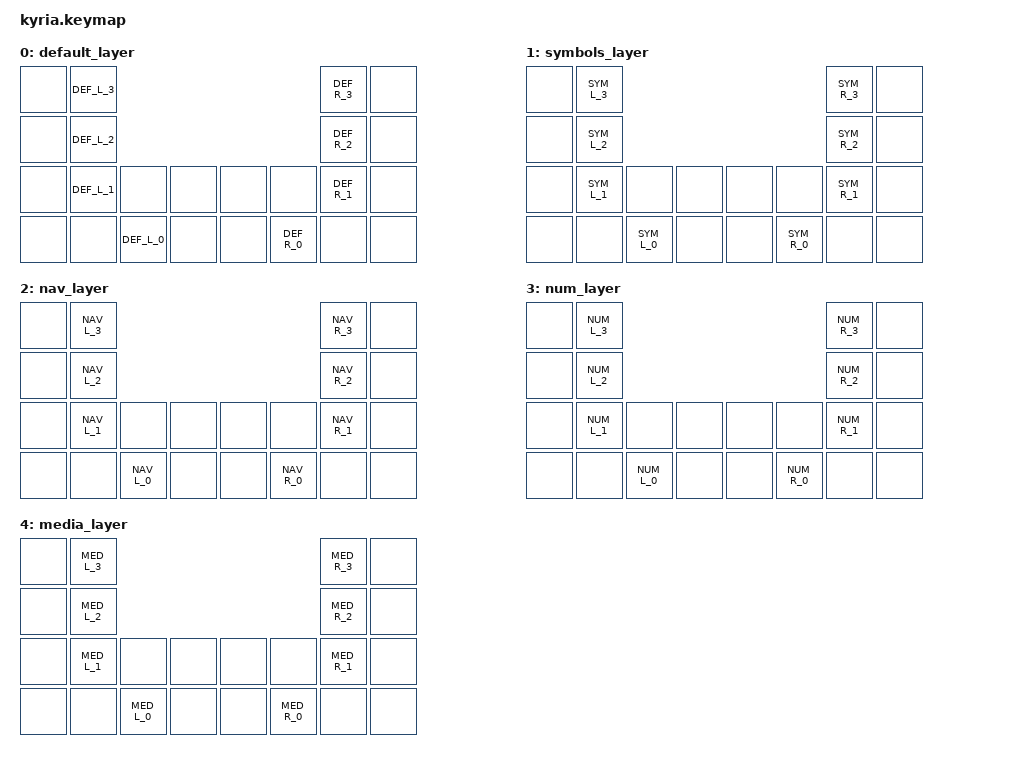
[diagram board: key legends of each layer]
/*
 * Copyright (c) 2020 The ZMK Contributors
 *
 * SPDX-License-Identifier: MIT
 */

#include <behaviors.dtsi>
#include <dt-bindings/zmk/keys.h>
#include <dt-bindings/zmk/bt.h>
#include <dt-bindings/zmk/ext_power.h>
#include <dt-bindings/zmk/outputs.h>

#include "common.h"
#include "common.keymap"


/ {
  keymap {
    compatible = "zmk,keymap";

    default_layer {
      bindings = <
              &none DEF_L_3                         DEF_R_3 &none
              &none DEF_L_2                         DEF_R_2 &none
              &none DEF_L_1 &none &none &none &none DEF_R_1 &none
        &none &none DEF_L_0 &none             &none DEF_R_0 &none &none
      >;
    };

    symbols_layer {
      bindings = <
              &none SYM_L_3                         SYM_R_3 &none
              &none SYM_L_2                         SYM_R_2 &none
              &none SYM_L_1 &none &none &none &none SYM_R_1 &none
        &none &none SYM_L_0 &none             &none SYM_R_0 &none &none
      >;
    };

    nav_layer {
      bindings = <
              &none NAV_L_3                         NAV_R_3 &none
              &none NAV_L_2                         NAV_R_2 &none
              &none NAV_L_1 &none &none &none &none NAV_R_1 &none
        &none &none NAV_L_0 &none             &none NAV_R_0 &none &none
      >;
    };

    num_layer {
      bindings = <
              &none NUM_L_3                         NUM_R_3 &none
              &none NUM_L_2                         NUM_R_2 &none
              &none NUM_L_1 &none &none &none &none NUM_R_1 &none
        &none &none NUM_L_0 &none             &none NUM_R_0 &none &none
      >;
    };

    media_layer {
      bindings = <
              &none MED_L_3                         MED_R_3 &none
              &none MED_L_2                         MED_R_2 &none
              &none MED_L_1 &none &none &none &none MED_R_1 &none
        &none &none MED_L_0 &none             &none MED_R_0 &none &none
      >;
    };
  };
};
